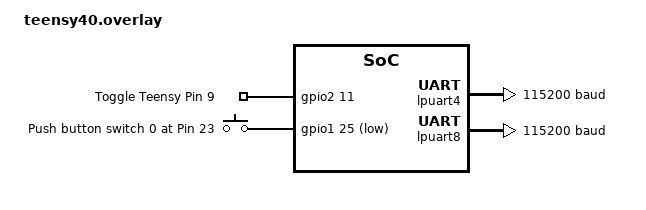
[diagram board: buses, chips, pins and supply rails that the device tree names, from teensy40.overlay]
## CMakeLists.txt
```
# Find Zephyr. This also loads Zephyr's build system.
cmake_minimum_required(VERSION 3.13.1)
# find_package(Zephyr)
find_package(Zephyr REQUIRED HINTS $ENV{ZEPHYR_BASE})
project(my_zephyr_app)

# Add your source file to the "app" target. This must come after
# find_package(Zephyr) which defines the target.
target_sources(app PRIVATE src/main.c)
target_sources(app PRIVATE src/led.c)
target_sources(app PRIVATE src/pin.c)
target_sources(app PRIVATE src/button.c)
target_sources(app PRIVATE src/uart.c)

include_directories(${CMAKE_CURRENT_SOURCE_DIR}/src)
```

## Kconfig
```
# Copyright (c) 2019 Nordic Semiconductor ASA
# SPDX-License-Identifier: Apache-2.0

config USB_DEVICE_PID
	default USB_PID_CONSOLE_SAMPLE

config LOG_BACKEND_UART
    bool "Enable UART backend"
    default y if !SHELL_BACKEND_SERIAL
    depends on UART_CONSOLE && !LOG_MINIMAL && LOG
    help
      When enabled backend is using UART to output logs.

source "Kconfig.zephyr"
```

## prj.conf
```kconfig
# enable logging and GPIO
CONFIG_LOG=y
CONFIG_GPIO=y

# Set following configs for USB and UART
CONFIG_USB=y
CONFIG_USB_DEVICE_STACK=y
CONFIG_USB_UART_CONSOLE=y
CONFIG_USB_DEVICE_PRODUCT="Zephyr first steps"
CONFIG_USB_DRIVER_LOG_LEVEL_ERR=y
CONFIG_UART_INTERRUPT_DRIVEN=y
CONFIG_UART_LINE_CTRL=y

# Floating Point Options
CONFIG_FPU=y
CONFIG_FPU_SHARING=y

# enable POSIX date and time api
CONFIG_POSIX_CLOCK=y

# enable the function sys_reboot()
CONFIG_REBOOT=y

# For using the shell
CONFIG_SHELL_PROMPT_UART="teensy:~$ "
CONFIG_PRINTK=y
CONFIG_SHELL=y
CONFIG_SHELL_BACKEND_SERIAL=y
CONFIG_UART_SHELL_ON_DEV_NAME="UART_6"
CONFIG_SHELL_LOG_BACKEND=y
CONFIG_OBJECT_TRACING=y
CONFIG_THREAD_MONITOR=y
CONFIG_INIT_STACKS=y
CONFIG_BOOT_BANNER=n
CONFIG_THREAD_NAME=y
CONFIG_SHELL_HISTORY=y
CONFIG_SHELL_STACK_SIZE=2048
CONFIG_SHELL_CMD_BUFF_SIZE=128
CONFIG_SHELL_WILDCARD=y
# CONFIG_SHELL_DYNAMIC_CMDS=n
CONFIG_SHELL_VT100_COLORS=y
CONFIG_SHELL_HELP_ON_WRONG_ARGUMENT_COUNT=y
CONFIG_SHELL_STATS=y
CONFIG_SHELL_CMDS=y
CONFIG_SHELL_HELP=y
CONFIG_SHELL_TAB=y
CONFIG_SHELL_METAKEYS=y
CONFIG_SHELL_LOG_BACKEND=y
CONFIG_KERNEL_SHELL=y
CONFIG_DEVICE_SHELL=y
CONFIG_DATE_SHELL=y
CONFIG_CBPRINTF_NANO=y
CONFIG_SENSOR_SHELL=n
CONFIG_SHELL_CMDS_SELECT=y
```

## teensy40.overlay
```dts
/*
 * Copyright (c) 2020, Bernhard Kraemer
 *
 * SPDX-License-Identifier: Apache-2.0
 */


/ {
    aliases {
            toggle = &toggle_gpio;
            sw0 = &button0;
    };
        
    app-gpios {
      compatible = "gpio-keys";
      toggle_gpio: toggle-gpio {
        gpios = <&gpio2 11 GPIO_ACTIVE_HIGH>;
        label = "Toggle Teensy Pin 9";
      };
      button0: button_0 {
        gpios = < &gpio1 25 GPIO_ACTIVE_LOW >;
        label = "Push button switch 0 at Pin 23";
      };
  };
};

&lpuart4 {
  status = "okay";
  current-speed = < 115200 >;
};

&lpuart8 {
  status = "okay";
  current-speed = < 115200 >;
};
```

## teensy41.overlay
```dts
/*
 * Copyright (c) 2020, Bernhard Kraemer
 *
 * SPDX-License-Identifier: Apache-2.0
 */


/ {
  aliases {
            toggle = &toggle_gpio;
            sw0 = &button0;
        };

    app-gpios {
      compatible = "gpio-keys";
      toggle_gpio: toggle-gpio {
        gpios = <&gpio1 21 GPIO_ACTIVE_HIGH>;
        label = "Toggle Pin 41";
      };
      button0: button_0 {
        gpios = < &gpio1 25 GPIO_ACTIVE_LOW >;
        label = "Push button switch 0 at Pin 23";
      };
    };
};

&lpuart4 {
  status = "okay";
  current-speed = < 115200 >;
};
```

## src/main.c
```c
/**
 * @file main.c
 * @author Bernhard Kraemer, Uwe Fechner
 * @brief Application startup
 * @version 0.3
 * @date 2020-12-28
 * 
 * @copyright Copyright (c) 2020
 * 
 */

/*** Imported Objects ***************************************************************/
#include <zephyr.h>
#include <logging/log.h>
#include <logging/log_ctrl.h>

#include <usb/usb_device.h>
#include <version.h>
#include <shell/shell.h>
#include <power/reboot.h>

#include "globals.h"

/*** Constants **********************************************************************/
#define LOG_MODULE_NAME sys

#define START_DELAY 420

/*** Initialize global variables ****************************************************/
bool blink_stat = true;

/*** Function Prototypes ************************************************************/
void main(void);

/*** Macros *************************************************************************/
LOG_MODULE_REGISTER(LOG_MODULE_NAME, LOG_LEVEL_DBG);

/*** Function implementation ********************************************************/

void main(void)
{
    const struct device *usb;
    uint32_t version = sys_kernel_version_get();

    usb = device_get_binding(CONFIG_UART_CONSOLE_ON_DEV_NAME);
    if (usb == NULL) {
        return;
    }

    log_init();
    if (usb_enable(NULL)) {
        return;
    }

    // sleep some time after boot to give USB-Client a chance to connect before first log output is produced
    k_msleep(START_DELAY);
    LOG_INF("Started zephyr %u.%u.%u on board %s.", SYS_KERNEL_VER_MAJOR(version), SYS_KERNEL_VER_MINOR(version), SYS_KERNEL_VER_PATCHLEVEL(version), CONFIG_BOARD);

    // this loop is needed to define how often log messages are processed
    while (true) {
        if (log_process(false) == false) {
            k_msleep(30);   /* sleep 30 ms*/
        }
    }
}

static int cmd_demo_ping(const struct shell *shell, size_t argc, char **argv)
{
    ARG_UNUSED(argc);
    ARG_UNUSED(argv);

    shell_print(shell, "pong");
    return 0;
}

static int cmd_demo_params(const struct shell *shell, size_t argc, char **argv)
{
    int cnt;

    shell_print(shell, "argc = %d", argc);
    for (cnt = 0; cnt < argc; cnt++) {
        shell_print(shell, "  argv[%d] = %s", cnt, argv[cnt]);
    }
    return 0;
}

static int cmd_blink(const struct shell *shell, size_t argc, char **argv)
{
    if (argc == 2) {
        if (strcmp(argv[1], "on") == 0) {
            shell_print(shell, "on");
            blink_stat = true;
            k_wakeup(led_id);
        } else if (strcmp(argv[1], "off") == 0) {
            shell_print(shell, "off");
            blink_stat = false;
            k_wakeup(led_id);
        } else {
            shell_print(shell, "Unknown parameter, must be 'on' or 'off'");
        }
    }
    return 0;
}

static int cmd_version(const struct shell *shell, size_t argc, char **argv)
{
    ARG_UNUSED(argc);
    ARG_UNUSED(argv);

    shell_print(shell, "Zephyr version %s", KERNEL_VERSION_STRING);

    return 0;
}

static int cmd_reboot(const struct shell *shell, size_t argc, char **argv)
{
    ARG_UNUSED(argc);
    ARG_UNUSED(argv);

    shell_print(shell, "Rebooting now...");
    k_msleep(200);

    sys_reboot(SYS_REBOOT_COLD);

    return 0;
}

/* Creating subcommands (level 1 command) array for command "demo". */
SHELL_STATIC_SUBCMD_SET_CREATE(sub_demo,
        SHELL_CMD(params, NULL, "Print params command.", cmd_demo_params),
        SHELL_CMD(ping,   NULL, "Ping command.", cmd_demo_ping),
        SHELL_SUBCMD_SET_END
);
/* Creating root (level 0) command "demo" without a handler */
SHELL_CMD_REGISTER(demo, &sub_demo, "Demo commands", NULL);

/* Creating root (level 0) command "version" */
SHELL_CMD_REGISTER(version, NULL, "Show kernel version", cmd_version);

/* Creating root (level 0) command "reboot" */
SHELL_CMD_REGISTER(reboot, NULL, "Reboot the system", cmd_reboot);

/* Creating root (level 0) command "blink" */
SHELL_CMD_ARG_REGISTER(blink, NULL, "Turn blinking on or off", cmd_blink, 2, 0);
```

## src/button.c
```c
/**
 * @file button.c
 * @author Bernhard Kraemer, Uwe Fechner
 * @brief Catch a debounced pushbutton state.
 * @version 0.1
 * @date 2020-11-16
 * 
 * @copyright Copyright (c) 2020
 * 
 */

/*** Imported Objects ***************************************************************/
#include <zephyr.h>
#include <logging/log.h>

#include <drivers/gpio.h>
#include <globals.h>

#include "stdio.h"
#include "string.h"

/*** Constants **********************************************************************/
#define LOG_MODULE_NAME but

#define START_DELAY     500
#define STACK_SIZE 1000
#define PRIORITY        5

#define SLEEP_TIME_MS   30

/*
 * Get button configuration from the devicetree sw0 alias.
 *
 * At least a GPIO device and pin number must be provided. The 'flags'
 * cell is optional.
 */
#define SW0_NODE DT_ALIAS(sw0)
#define SW0_GPIO_LABEL DT_GPIO_LABEL(SW0_NODE, gpios)
#define SW0_GPIO_PIN DT_GPIO_PIN(SW0_NODE, gpios)
#define SW0_GPIO_FLAGS (GPIO_INT_DEBOUNCE | GPIO_INPUT | DT_GPIO_FLAGS(SW0_NODE, gpios))

/*** Function Prototypes ************************************************************/
void button_main_f();

/*** Macros *************************************************************************/
LOG_MODULE_REGISTER(LOG_MODULE_NAME, LOG_LEVEL_DBG);

K_THREAD_DEFINE(button_id, STACK_SIZE, button_main_f, NULL, NULL, NULL,
                PRIORITY, 0, START_DELAY);

K_MSGQ_DEFINE(data_message_q, sizeof(data_message_t), 10, 4);

/*** Function implementation ********************************************************/

void button_main_f()
{
    const struct device *button;
    int ret;
    bool currentState = 0;
    bool newState = 0;

    button = device_get_binding(SW0_GPIO_LABEL);
    if (button == NULL) {
        LOG_ERR("Error: didn't find %s device", SW0_GPIO_LABEL);
        return;
    }

    ret = gpio_pin_configure(button, SW0_GPIO_PIN, SW0_GPIO_FLAGS);
    if (ret != 0) {
        LOG_ERR("Error %d: failed to configure %s pin %d, flags %u",
               ret, SW0_GPIO_LABEL, SW0_GPIO_PIN, SW0_GPIO_FLAGS);
        return;
    }

    LOG_INF("Set up button at %s pin %d", SW0_GPIO_LABEL, SW0_GPIO_PIN);

    while(true) {
        newState = gpio_pin_get(button, SW0_GPIO_PIN); 
        if (newState != currentState) {
            LOG_DBG("Button state is now %u", newState);
            currentState = newState;

            char s[20];
            sprintf(s, "Button state is %u\r\n", newState);
            data_message_t msg;
            memcpy(msg.data, (uint8_t *)s, strlen(s));
            msg.length = strlen(s);

            while (k_msgq_put(&data_message_q, &msg, K_NO_WAIT) != 0) {
                /* message queue is full: purge old data & try again */
                k_msgq_purge(&data_message_q);
                LOG_ERR("Data message queue is full -- purge");
            }
        }
        k_msleep(SLEEP_TIME_MS);
    }
}
```

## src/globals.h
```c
/**
 * @file globals.h
 * @author Bernhard Kraemer, Uwe Fechner
 * @brief Project globals
 * @version 0.2
 * @date 2020-12-28
 * 
 * @copyright Copyright (c) 2020
 * 
 */

#ifndef GLOBALS_H_
#define GLOBALS_H_

/*** Constants **********************************************************************/

/*** Types **************************************************************************/
typedef struct {
    uint32_t length;
    uint8_t data[50];
}__attribute__((aligned(4))) data_message_t;

/*** Variables **********************************************************************/
extern bool blink_stat;      /* true = blinking, false = off */
extern const k_tid_t led_id; /* the id of the led thread */

#endif /* GLOBALS_H_ */
```

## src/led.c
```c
/**
 * @file led.c
 * @author Bernhard Kraemer, Uwe Fechner
 * @brief Toggle board led periodically.
 * @version 0.2
 * @date 2021-01-02
 * 
 * @copyright Copyright (c) 2020
 * 
 */

/*** Imported Objects ***************************************************************/
#include <zephyr.h>
#include <logging/log.h>

#include <drivers/gpio.h>

#include "globals.h"

/*** Constants **********************************************************************/
#define LOG_MODULE_NAME led

#define START_DELAY     500
#define STACK_SIZE      500
#define PRIORITY        5

#define TOGGLE_TIME_MS  1000

/* The devicetree node identifier for the "led0" alias. */
#define LED0_NODE DT_ALIAS(led0)
#define LED0_GPIO_LABEL DT_GPIO_LABEL(LED0_NODE, gpios)
#define LED0_GPIO_PIN DT_GPIO_PIN(LED0_NODE, gpios)
#define LED0_GPIO_FLAGS DT_GPIO_FLAGS(LED0_NODE, gpios)

/*** Function Prototypes ************************************************************/
void led_main_f();

/*** Macros *************************************************************************/
LOG_MODULE_REGISTER(LOG_MODULE_NAME, LOG_LEVEL_INF);

K_THREAD_DEFINE(led_id, STACK_SIZE, led_main_f, NULL, NULL, NULL,
                PRIORITY, 0, START_DELAY);

/*** Function implementation ********************************************************/

void led_main_f()
{
    bool led_is_on = true;
    const struct device *dev;

    dev = device_get_binding(LED0_GPIO_LABEL);
    if (dev == NULL) {
        LOG_ERR("Device binding is NULL");
        return;
    }

    if (gpio_pin_configure(dev, LED0_GPIO_PIN, GPIO_OUTPUT_ACTIVE | LED0_GPIO_FLAGS)) {
        LOG_ERR("GPIO configuration failed");
        return;
    }

    LOG_INF("Thread started");

    while (true) {
        gpio_pin_set(dev, LED0_GPIO_PIN, (int)led_is_on);

        LOG_DBG("LED state changed: %u", (int)led_is_on);

        if (blink_stat) {
            led_is_on = !led_is_on;
        } else {
            led_is_on = false;
        }

        /* make sure that the LED immediately turns on when the command
           "blink on" is executed */
        if (k_msleep(TOGGLE_TIME_MS)) {
            if (blink_stat) {
                led_is_on = true;
            }
        };
    }
}
```

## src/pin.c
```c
/**
 * @file pin.c
 * @author Bernhard Kraemer, Uwe Fechner
 * @brief Toggle a pin periodically.
 * @version 0.2
 * @date 2021-01-02
 * 
 * @copyright Copyright (c) 2020
 * 
 */

/*** Imported Objects ***************************************************************/
#include <zephyr.h>
#include <logging/log.h>

#include <drivers/gpio.h>

/*** Constants **********************************************************************/
#define LOG_MODULE_NAME pin

#define START_DELAY     500
#define STACK_SIZE      500
#define PRIORITY        5

#define TOGGLE_TIME_MS  493

/* The devicetree node identifier for the "toggle" alias. */
#define TOGGLE_NODE DT_ALIAS(toggle)
#define TOGGLE_GPIO_LABEL DT_GPIO_LABEL(TOGGLE_NODE, gpios)
#define TOGGLE_GPIO_PIN DT_GPIO_PIN(TOGGLE_NODE, gpios)
#define TOGGLE_GPIO_FLAGS DT_GPIO_FLAGS(TOGGLE_NODE, gpios)

/*** Function Prototypes ************************************************************/
void pin_main_f();

/*** Macros *************************************************************************/
LOG_MODULE_REGISTER(LOG_MODULE_NAME, LOG_LEVEL_INF);

K_THREAD_DEFINE(pin_id, STACK_SIZE, pin_main_f, NULL, NULL, NULL,
                PRIORITY, 0, START_DELAY);

/*** Function implementation ********************************************************/

void pin_main_f()
{
    const struct device *dev;
    bool pin_is_on = true;

    dev = device_get_binding(TOGGLE_GPIO_LABEL);
    if (dev == NULL) {
        LOG_ERR("Device binding is NULL");
        return;
    }

    if (gpio_pin_configure(dev, TOGGLE_GPIO_PIN, GPIO_OUTPUT_ACTIVE | TOGGLE_GPIO_FLAGS)) {
        LOG_ERR("GPIO configuration failed");
        return;
    }

    LOG_INF("Pin thread started");
    LOG_INF(TOGGLE_GPIO_LABEL);
    LOG_INF("PIN %u", (int)TOGGLE_GPIO_PIN);

    while (true) {
        gpio_pin_set(dev, TOGGLE_GPIO_PIN, (int)pin_is_on);

        LOG_DBG("PIN state changed: %u", (int)pin_is_on);

        pin_is_on = !pin_is_on;

        k_msleep(TOGGLE_TIME_MS);
    }
}
```

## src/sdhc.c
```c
/**
 * @file sdhc.c
 * @author Bernhard Kraemer
 * @brief Access SD-Card with FAT Filesystem
 * @version 0.1
 * @date 2020-11-19
 * 
 * @copyright Copyright (c) 2020
 * 
 */

/*** Imported Objects ***************************************************************/
#include <zephyr.h>
#include <logging/log.h>

#include <disk/disk_access.h>
#include <fs/fs.h>
#include <ff.h>

#include <globals.h>

/*** Constants **********************************************************************/
#define LOG_MODULE_NAME sdhc

#define START_DELAY     500
#define STACK_SIZE      2000
#define PRIORITY        5

/*** Types **************************************************************************/

/*** Variables **********************************************************************/
static int lsdir(const char *path);

static FATFS fat_fs;
/* mounting info */
static struct fs_mount_t mp = {
	.type = FS_FATFS,
	.fs_data = &fat_fs,
};

/*
*  Note the fatfs library is able to mount only strings inside _VOLUME_STRS
*  in ffconf.h
*/
static const char *disk_mount_pt = "/SD:";

/*** Function Prototypes ************************************************************/
void sdhc_main_f();
static int lsdir(const char *path);

/*** Macros *************************************************************************/
LOG_MODULE_REGISTER(LOG_MODULE_NAME, LOG_LEVEL_DBG);

K_THREAD_DEFINE(sdhc_id, STACK_SIZE, sdhc_main_f, NULL, NULL, NULL,
                PRIORITY, 0, START_DELAY);

/*** Function implementation ********************************************************/

void sdhc_main_f()
{
    /* raw disk i/o */
	do {
		static const char *disk_pdrv = "SD";
		uint64_t memory_size_mb;
		uint32_t block_count;
		uint32_t block_size;

		if (disk_access_init(disk_pdrv) != 0) {
			LOG_ERR("Storage init ERROR!");
			return;
		}

		if (disk_access_ioctl(disk_pdrv,
				DISK_IOCTL_GET_SECTOR_COUNT, &block_count)) {
			LOG_ERR("Unable to get sector count");
			return;
		}
		LOG_INF("Block count %u", block_count);

		if (disk_access_ioctl(disk_pdrv,
				DISK_IOCTL_GET_SECTOR_SIZE, &block_size)) {
			LOG_ERR("Unable to get sector size");
			return;
		}
		LOG_INF("Sector size %u", block_size);

		memory_size_mb = (uint64_t)block_count * block_size;
		LOG_INF("Memory Size(MB) %u", (uint32_t)(memory_size_mb >> 20));
	} while (0);

	mp.mnt_point = disk_mount_pt;

	int res = fs_mount(&mp);

	if (res == FR_OK) {
		LOG_INF("Disk mounted.");
		lsdir(disk_mount_pt);
	} else {
		LOG_INF("Error mounting disk.");
	}
}

static int lsdir(const char *path)
{
	int res;
	struct fs_dir_t dirp;
	static struct fs_dirent entry;

	/* Verify fs_opendir() */
	res = fs_opendir(&dirp, path);
	if (res) {
		LOG_INF("Error opening dir %s [%d]", path, res);
		return res;
	}

	LOG_INF("Listing dir %s ...", path);
	for (;;) 
    {
		/* Verify fs_readdir() */
		res = fs_readdir(&dirp, &entry);

		/* entry.name[0] == 0 means end-of-dir */
		if (res || entry.name[0] == 0) {
			break;
		}

		if (entry.type == FS_DIR_ENTRY_DIR) {
			LOG_INF("[DIR] %s", log_strdup(entry.name));
		} else {
			LOG_INF("[FILE] %s", log_strdup(entry.name));
		}
	}

	/* Verify fs_closedir() */
	fs_closedir(&dirp);

	return res;
}
```

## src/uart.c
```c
/**
 * @file uart.c
 * @author Bernhard Kraemer, Uwe Fechner
 * @brief Uart mirror with message queue.
 * @version 0.2
 * @date 2021-01-02
 * 
 * @copyright Copyright (c) 2020
 * 
 */

/*** Imported Objects ***************************************************************/
#include <zephyr.h>
#include <logging/log.h>

#include <drivers/uart.h>
#include <globals.h>

/*** Constants **********************************************************************/
#define LOG_MODULE_NAME uart

#define START_DELAY     500
#define STACK_SIZE      500
#define PRIORITY        -5

#define UART_DEV        DT_LABEL(DT_NODELABEL(lpuart4))

/*** Types **************************************************************************/
extern struct k_msgq data_message_q; 

/*** Variables **********************************************************************/
static volatile bool tx_done;
static data_message_t tx_msg;

/*** Function Prototypes ************************************************************/
void uart_main_f();
static void uart_fifo_cb(const struct device *dev, void *user_data);

/*** Macros *************************************************************************/
LOG_MODULE_REGISTER(LOG_MODULE_NAME, LOG_LEVEL_DBG);

K_THREAD_DEFINE(uart_id, STACK_SIZE, uart_main_f, NULL, NULL, NULL,
                PRIORITY, 0, START_DELAY);

/*** Function implementation ********************************************************/

void uart_main_f()
{
    const struct device *uart;

    uart = device_get_binding(UART_DEV);
    if (uart == NULL) {
        LOG_ERR("Device binding is NULL");
        return;
    }

    // struct uart_config cfg;
    // cfg.baudrate=115200;
    // cfg.parity=UART_CFG_PARITY_NONE;
    // cfg.stop_bits=UART_CFG_STOP_BITS_1;
    // cfg.data_bits=UART_CFG_DATA_BITS_8;
    // cfg.flow_ctrl=UART_CFG_FLOW_CTRL_NONE;

    // ret = uart_configure(uart, &cfg);
    // if (ret != 0)
    // {
    //     LOG_ERR("Failed to configure %s, Error: %u", UART_DEV, ret);
    //     return;
    // }

    uart_irq_callback_set(uart, uart_fifo_cb);
    uart_irq_rx_enable(uart);

    LOG_INF("UART thread started");
    
    while (true) {
        /* get a data item */
        k_msgq_get(&data_message_q, &tx_msg, K_FOREVER);
        tx_done=false;
        uart_irq_tx_enable(uart);

        while(!tx_done){}
    }
}

static void uart_fifo_cb(const struct device *dev, void *user_data)
{
    static data_message_t rx_msg;
    static int tx_data_idx;

    uart_irq_update(dev);

    if (uart_irq_tx_ready(dev) && tx_data_idx < tx_msg.length) {
        uart_fifo_fill(dev, &tx_msg.data[tx_data_idx++], 1);

        if (tx_data_idx == tx_msg.length) {
            uart_irq_tx_disable(dev);
            tx_done=true;
            tx_data_idx=0;
        }
    }

    if (uart_irq_rx_ready(dev)) {
        uart_fifo_read(dev, &rx_msg.data[rx_msg.length++], 1);

        if ((rx_msg.data[rx_msg.length] == '\n') || (rx_msg.data[rx_msg.length - 1] == '\r')) {
            LOG_HEXDUMP_DBG((const uint8_t *)&rx_msg.data, rx_msg.length, "Received data:");
            rx_msg.length=0;
        }
    }
}
```
